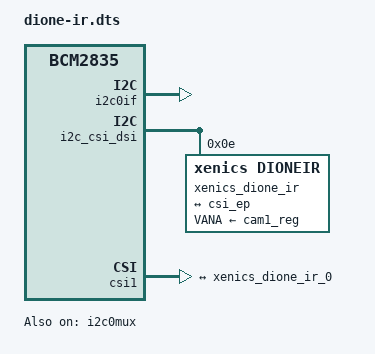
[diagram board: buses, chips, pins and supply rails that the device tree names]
// SPDX-License-Identifier: GPL-2.0-only
// Definitions for Xenics Dione camera module on VC I2C bus
/dts-v1/;
/plugin/;

/{
	compatible = "brcm,bcm2835";

	/* ===== CAM1 path (default, RPi4-compatible) ===== */

	fragment@0 {
		target = <&i2c0if>;
		__overlay__ {
			status = "okay";
		};
	};

	clk_frag: fragment@1 {
		target = <&cam1_clk>;
		__overlay__ {
			status = "okay";
			clock-frequency = <24000000>;
		};
	};

	fragment@2 {
		target = <&i2c0mux>;
		__overlay__ {
			status = "okay";
		};
	};

	i2c_frag: fragment@3 {
		target = <&i2c_csi_dsi>;
		__overlay__ {
			#address-cells = <1>;
			#size-cells = <0>;
			status = "okay";

			xenics_dione_ir: xenics_dione_ir@0e {
				compatible = "xenics,dioneir";
				reg = <0x0e>;
				status = "okay";

				fpga-address = <0x5a 0x5b 0x5c 0x5d>;

				clocks = <&cam1_clk>;
				clock-names = "xclk";

				VANA-supply = <&cam1_reg>;

				rotation = <180>;
				orientation = <2>;

				port {
					xenics_dione_ir_0: endpoint {
						remote-endpoint = <&csi_ep>;
						data-lanes = <1 2>;
						clock-lanes = <0>;
						link-frequencies = /bits/ 64 <120000000 498000000>;
					};
				};
			};

			vcm: ad5398@0c {
				compatible = "adi,ad5398";
				reg = <0x0c>;
				status = "disabled";
				VANA-supply = <&cam1_reg>;
			};
		};
	};

	csi_frag: fragment@4 {
		target = <&csi1>;
		csi: __overlay__ {
			status = "okay";
			brcm,media-controller;

			port {
				csi_ep: endpoint {
					remote-endpoint = <&xenics_dione_ir_0>;
					data-lanes = <1 2>;
					clock-lanes = <0>;
					link-frequencies = /bits/ 64 <120000000 498000000>;
				};
			};
		};
	};

	/* ===== CAM0 path (dormant by default, RPi5 only) ===== */

	fragment@5 {
		target = <&cam0_clk>;
		__dormant__ {
			status = "okay";
			clock-frequency = <24000000>;
		};
	};

	fragment@6 {
		target = <&i2c_csi_dsi0>;
		__dormant__ {
			#address-cells = <1>;
			#size-cells = <0>;
			status = "okay";

			xenics_dione_ir_cam0: xenics_dione_ir@0e {
				compatible = "xenics,dioneir";
				reg = <0x0e>;
				status = "okay";

				fpga-address = <0x5a 0x5b 0x5c 0x5d>;

				clocks = <&cam0_clk>;
				clock-names = "xclk";

				VANA-supply = <&cam0_reg>;

				rotation = <180>;
				orientation = <2>;

				port {
					xenics_dione_ir_cam0_0: endpoint {
						remote-endpoint = <&csi0_ep>;
						data-lanes = <1 2>;
						clock-lanes = <0>;
						link-frequencies = /bits/ 64 <120000000 497000000>;
					};
				};
			};
		};
	};

	fragment@7 {
		target = <&csi0>;
		__dormant__ {
			status = "okay";
			brcm,media-controller;

			port {
				csi0_ep: endpoint {
					remote-endpoint = <&xenics_dione_ir_cam0_0>;
					data-lanes = <1 2>;
					clock-lanes = <0>;
					link-frequencies = /bits/ 64 <120000000 497000000>;
				};
			};
		};
	};

	__overrides__ {
		/* Switch all fragments to CAM0 path; deactivates i2c0if/mux (RPi4-only) */
		cam0 = <0>, "-0-1-2-3-4+5+6+7";
		/* Restore CAM1 path (symmetric inverse of cam0) */
		cam1 = <0>, "+0+1+2+3+4-5-6-7";
	};
};
